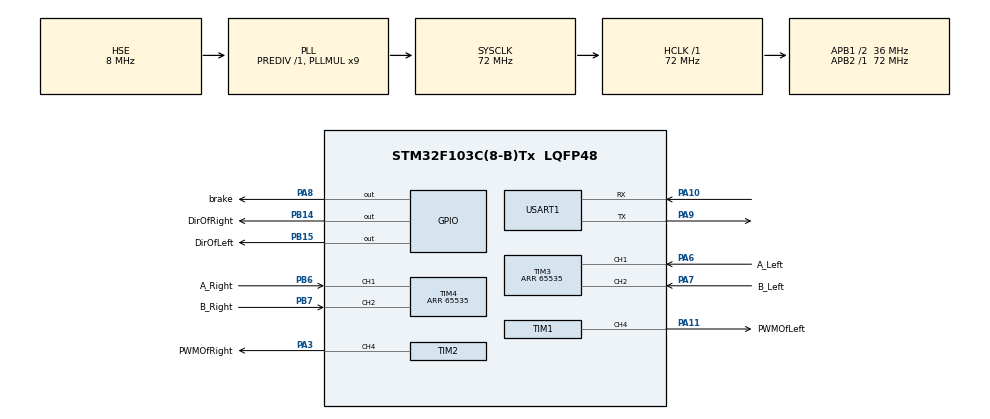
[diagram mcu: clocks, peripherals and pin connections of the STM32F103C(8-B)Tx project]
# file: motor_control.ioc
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Dma.Request0=USART1_TX
Dma.Request1=USART1_RX
Dma.USART1_RX.1.Direction=DMA_PERIPH_TO_MEMORY
Dma.USART1_RX.1.Instance=DMA1_Channel5
Dma.USART1_RX.1.MemDataAlignment=DMA_MDATAALIGN_BYTE
Dma.USART1_RX.1.MemInc=DMA_MINC_ENABLE
Dma.USART1_RX.1.Mode=DMA_CIRCULAR
Dma.USART1_RX.1.PeriphDataAlignment=DMA_PDATAALIGN_BYTE
Dma.USART1_RX.1.PeriphInc=DMA_PINC_DISABLE
Dma.USART1_RX.1.Priority=DMA_PRIORITY_MEDIUM
Dma.USART1_TX.0.Direction=DMA_MEMORY_TO_PERIPH
Dma.USART1_TX.0.Instance=DMA1_Channel4
Dma.USART1_TX.0.MemDataAlignment=DMA_MDATAALIGN_BYTE
Dma.USART1_TX.0.MemInc=DMA_MINC_ENABLE
Dma.USART1_TX.0.Mode=DMA_NORMAL
Dma.USART1_TX.0.PeriphDataAlignment=DMA_PDATAALIGN_BYTE
Dma.USART1_TX.0.PeriphInc=DMA_PINC_DISABLE
Dma.USART1_TX.0.Priority=DMA_PRIORITY_MEDIUM
Mcu.Family=STM32F1
Mcu.Name=STM32F103C(8-B)Tx
Mcu.Package=LQFP48
NVIC.DMA1_Channel4_IRQn=true\:3\:0\:true\:false\:true\:false\:true
NVIC.DMA1_Channel5_IRQn=true\:3\:0\:true\:false\:true\:false\:true
NVIC.PriorityGroup=NVIC_PRIORITYGROUP_4
NVIC.USART1_IRQn=true\:0\:0\:false\:false\:true\:true\:true
PA10.Mode=Asynchronous
PA10.Signal=USART1_RX
PA11.GPIO_Label=PWMOfLeft
PA11.Signal=S_TIM1_CH4
PA13.Mode=Serial_Wire
PA13.Signal=SYS_JTMS-SWDIO
PA14.Mode=Serial_Wire
PA14.Signal=SYS_JTCK-SWCLK
PA3.GPIO_Label=PWMOfRight
PA3.Signal=S_TIM2_CH4
PA6.GPIO_Label=A_Left
PA6.GPIO_PuPd=GPIO_PULLUP
PA6.Signal=S_TIM3_CH1
PA7.GPIO_Label=B_Left
PA7.GPIO_PuPd=GPIO_PULLUP
PA7.Signal=S_TIM3_CH2
PA8.GPIO_Label=brake
PA8.GPIO_PuPd=GPIO_PULLUP
PA8.Signal=GPIO_Output
PA9.Mode=Asynchronous
PA9.Signal=USART1_TX
PB14.GPIO_Label=DirOfRight
PB14.GPIO_Speed=GPIO_SPEED_FREQ_MEDIUM
PB14.PinState=GPIO_PIN_RESET
PB14.Signal=GPIO_Output
PB15.GPIO_Label=DirOfLeft
PB15.GPIO_Speed=GPIO_SPEED_FREQ_MEDIUM
PB15.Signal=GPIO_Output
PB6.GPIO_Label=A_Right
PB6.GPIO_PuPd=GPIO_PULLUP
PB6.Signal=S_TIM4_CH1
PB7.GPIO_Label=B_Right
PB7.GPIO_PuPd=GPIO_PULLUP
PB7.Signal=S_TIM4_CH2
PD0-OSC_IN.Mode=HSE-External-Oscillator
PD0-OSC_IN.Signal=RCC_OSC_IN
PD1-OSC_OUT.Mode=HSE-External-Oscillator
PD1-OSC_OUT.Signal=RCC_OSC_OUT
ProjectManager.HeapSize=0x200
ProjectManager.StackSize=0x400
ProjectManager.TargetToolchain=STM32CubeIDE
RCC.AHBFreq_Value=72000000
RCC.APB1CLKDivider=RCC_HCLK_DIV2
RCC.APB1Freq_Value=36000000
RCC.APB1TimFreq_Value=72000000
RCC.APB2Freq_Value=72000000
RCC.APB2TimFreq_Value=72000000
RCC.HCLKFreq_Value=72000000
RCC.PLLMUL=RCC_PLL_MUL9
RCC.PLLSourceVirtual=RCC_PLLSOURCE_HSE
RCC.SYSCLKFreq_VALUE=72000000
RCC.SYSCLKSource=RCC_SYSCLKSOURCE_PLLCLK
RCC.USBFreq_Value=72000000
SH.S_TIM1_CH4.0=TIM1_CH4,PWM Generation4 CH4
SH.S_TIM2_CH4.0=TIM2_CH4,PWM Generation4 CH4
SH.S_TIM3_CH1.0=TIM3_CH1,Encoder_Interface
SH.S_TIM3_CH2.0=TIM3_CH2,Encoder_Interface
SH.S_TIM4_CH1.0=TIM4_CH1,Encoder_Interface
SH.S_TIM4_CH2.0=TIM4_CH2,Encoder_Interface
TIM1.Channel-PWM\ Generation4\ CH4=TIM_CHANNEL_4
TIM1.Period=10001
TIM1.Prescaler=0
TIM2.Channel-PWM\ Generation4\ CH4=TIM_CHANNEL_4
TIM2.Period=10001
TIM2.Prescaler=0
TIM3.EncoderMode=TIM_ENCODERMODE_TI12
TIM3.IC1Filter=5
TIM3.IC2Filter=5
TIM3.Period=65535
TIM4.EncoderMode=TIM_ENCODERMODE_TI12
TIM4.IC1Filter=5
TIM4.IC2Filter=5
TIM4.Period=65535
USART1.VirtualMode=VM_ASYNC
board=custom

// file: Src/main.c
/* USER CODE BEGIN Header */
/**
  ******************************************************************************
  * @file           : main.c
  * @brief          : Main program body
  ******************************************************************************
  * @attention
  *
  * <h2><center>&copy; Copyright (c) 2019 STMicroelectronics.
  * All rights reserved.</center></h2>
  *
  * This software component is licensed by ST under BSD 3-Clause license,
  * the "License"; You may not use this file except in compliance with the
  * License. You may obtain a copy of the License at:
  *                        opensource.org/licenses/BSD-3-Clause
  *
  ******************************************************************************
  */
/* USER CODE END Header */

#include "main.h"

/* USER CODE BEGIN Includes */
#include "motor.h"
#include "my_uart.h"
/* USER CODE END Includes */

TIM_HandleTypeDef htim1;
TIM_HandleTypeDef htim2;
TIM_HandleTypeDef htim3;
TIM_HandleTypeDef htim4;

UART_HandleTypeDef huart1;
DMA_HandleTypeDef hdma_usart1_tx;
DMA_HandleTypeDef hdma_usart1_rx;

void SystemClock_Config(void);
static void MX_GPIO_Init(void);
static void MX_DMA_Init(void);
static void MX_TIM1_Init(void);
static void MX_TIM2_Init(void);
static void MX_TIM3_Init(void);
static void MX_TIM4_Init(void);
static void MX_USART1_UART_Init(void);

int main(void)
{
  /* USER CODE BEGIN 1 */
	uint8_t data[11];
	FloatToUnsignedChar ftuc;
  /* USER CODE END 1 */

  /* MCU Configuration--------------------------------------------------------*/

  /* Reset of all peripherals, Initializes the Flash interface and the Systick. */
  HAL_Init();

  /* Configure the system clock */
  SystemClock_Config();

  /* Initialize all configured peripherals */
  MX_GPIO_Init();
  MX_DMA_Init();
  MX_TIM1_Init();
  MX_TIM2_Init();
  MX_TIM3_Init();
  MX_TIM4_Init();
  MX_USART1_UART_Init();
  /* USER CODE BEGIN 2 */
  motor_init();
  my_uart_init();
  /* USER CODE END 2 */

  /* Infinite loop */
  /* USER CODE BEGIN WHILE */
  while (1)
  {
	data[0]=0xed;data[10]=0xde;data[5]=0xaa;
	ftuc.F32=x_position;
	data[1]=ftuc.U8.low;data[2]=ftuc.U8.mlow;data[3]=ftuc.U8.mhigh;data[4]=ftuc.U8.high;
	ftuc.F32=y_position;
	data[6]=ftuc.U8.low;data[7]=ftuc.U8.mlow;data[8]=ftuc.U8.mhigh;data[9]=ftuc.U8.high;
	HAL_UART_Transmit_DMA(&huart1, data, 11);
	HAL_Delay(15);
    /* USER CODE END WHILE */

  }
}

void SystemClock_Config(void)
{
  RCC_OscInitTypeDef RCC_OscInitStruct = {0};
  RCC_ClkInitTypeDef RCC_ClkInitStruct = {0};

  /** Initializes the CPU, AHB and APB busses clocks
  */
  RCC_OscInitStruct.OscillatorType = RCC_OSCILLATORTYPE_HSE;
  RCC_OscInitStruct.HSEState = RCC_HSE_ON;
  RCC_OscInitStruct.HSEPredivValue = RCC_HSE_PREDIV_DIV1;
  RCC_OscInitStruct.HSIState = RCC_HSI_ON;
  RCC_OscInitStruct.PLL.PLLState = RCC_PLL_ON;
  RCC_OscInitStruct.PLL.PLLSource = RCC_PLLSOURCE_HSE;
  RCC_OscInitStruct.PLL.PLLMUL = RCC_PLL_MUL9;
  if (HAL_RCC_OscConfig(&RCC_OscInitStruct) != HAL_OK)
  {
    Error_Handler();
  }
  /** Initializes the CPU, AHB and APB busses clocks
  */
  RCC_ClkInitStruct.ClockType = RCC_CLOCKTYPE_HCLK|RCC_CLOCKTYPE_SYSCLK
                              |RCC_CLOCKTYPE_PCLK1|RCC_CLOCKTYPE_PCLK2;
  RCC_ClkInitStruct.SYSCLKSource = RCC_SYSCLKSOURCE_PLLCLK;
  RCC_ClkInitStruct.AHBCLKDivider = RCC_SYSCLK_DIV1;
  RCC_ClkInitStruct.APB1CLKDivider = RCC_HCLK_DIV2;
  RCC_ClkInitStruct.APB2CLKDivider = RCC_HCLK_DIV1;

  if (HAL_RCC_ClockConfig(&RCC_ClkInitStruct, FLASH_LATENCY_2) != HAL_OK)
  {
    Error_Handler();
  }
}

static void MX_TIM1_Init(void)
{

  TIM_MasterConfigTypeDef sMasterConfig = {0};
  TIM_OC_InitTypeDef sConfigOC = {0};
  TIM_BreakDeadTimeConfigTypeDef sBreakDeadTimeConfig = {0};

  htim1.Instance = TIM1;
  htim1.Init.Prescaler = 0;
  htim1.Init.CounterMode = TIM_COUNTERMODE_UP;
  htim1.Init.Period = 10001;
  htim1.Init.ClockDivision = TIM_CLOCKDIVISION_DIV1;
  htim1.Init.RepetitionCounter = 0;
  htim1.Init.AutoReloadPreload = TIM_AUTORELOAD_PRELOAD_DISABLE;
  if (HAL_TIM_PWM_Init(&htim1) != HAL_OK)
  {
    Error_Handler();
  }
  sMasterConfig.MasterOutputTrigger = TIM_TRGO_RESET;
  sMasterConfig.MasterSlaveMode = TIM_MASTERSLAVEMODE_DISABLE;
  if (HAL_TIMEx_MasterConfigSynchronization(&htim1, &sMasterConfig) != HAL_OK)
  {
    Error_Handler();
  }
  sConfigOC.OCMode = TIM_OCMODE_PWM1;
  sConfigOC.Pulse = 0;
  sConfigOC.OCPolarity = TIM_OCPOLARITY_HIGH;
  sConfigOC.OCFastMode = TIM_OCFAST_DISABLE;
  sConfigOC.OCIdleState = TIM_OCIDLESTATE_RESET;
  sConfigOC.OCNIdleState = TIM_OCNIDLESTATE_RESET;
  if (HAL_TIM_PWM_ConfigChannel(&htim1, &sConfigOC, TIM_CHANNEL_4) != HAL_OK)
  {
    Error_Handler();
  }
  sBreakDeadTimeConfig.OffStateRunMode = TIM_OSSR_DISABLE;
  sBreakDeadTimeConfig.OffStateIDLEMode = TIM_OSSI_DISABLE;
  sBreakDeadTimeConfig.LockLevel = TIM_LOCKLEVEL_OFF;
  sBreakDeadTimeConfig.DeadTime = 0;
  sBreakDeadTimeConfig.BreakState = TIM_BREAK_DISABLE;
  sBreakDeadTimeConfig.BreakPolarity = TIM_BREAKPOLARITY_HIGH;
  sBreakDeadTimeConfig.AutomaticOutput = TIM_AUTOMATICOUTPUT_DISABLE;
  if (HAL_TIMEx_ConfigBreakDeadTime(&htim1, &sBreakDeadTimeConfig) != HAL_OK)
  {
    Error_Handler();
  }
  HAL_TIM_MspPostInit(&htim1);

}

static void MX_TIM2_Init(void)
{

  TIM_MasterConfigTypeDef sMasterConfig = {0};
  TIM_OC_InitTypeDef sConfigOC = {0};

  htim2.Instance = TIM2;
  htim2.Init.Prescaler = 0;
  htim2.Init.CounterMode = TIM_COUNTERMODE_UP;
  htim2.Init.Period = 10001;
  htim2.Init.ClockDivision = TIM_CLOCKDIVISION_DIV1;
  htim2.Init.AutoReloadPreload = TIM_AUTORELOAD_PRELOAD_DISABLE;
  if (HAL_TIM_PWM_Init(&htim2) != HAL_OK)
  {
    Error_Handler();
  }
  sMasterConfig.MasterOutputTrigger = TIM_TRGO_RESET;
  sMasterConfig.MasterSlaveMode = TIM_MASTERSLAVEMODE_DISABLE;
  if (HAL_TIMEx_MasterConfigSynchronization(&htim2, &sMasterConfig) != HAL_OK)
  {
    Error_Handler();
  }
  sConfigOC.OCMode = TIM_OCMODE_PWM1;
  sConfigOC.Pulse = 0;
  sConfigOC.OCPolarity = TIM_OCPOLARITY_HIGH;
  sConfigOC.OCFastMode = TIM_OCFAST_DISABLE;
  if (HAL_TIM_PWM_ConfigChannel(&htim2, &sConfigOC, TIM_CHANNEL_4) != HAL_OK)
  {
    Error_Handler();
  }
  HAL_TIM_MspPostInit(&htim2);

}

static void MX_TIM3_Init(void)
{

  TIM_Encoder_InitTypeDef sConfig = {0};
  TIM_MasterConfigTypeDef sMasterConfig = {0};

  htim3.Instance = TIM3;
  htim3.Init.Prescaler = 0;
  htim3.Init.CounterMode = TIM_COUNTERMODE_UP;
  htim3.Init.Period = 65535;
  htim3.Init.ClockDivision = TIM_CLOCKDIVISION_DIV1;
  htim3.Init.AutoReloadPreload = TIM_AUTORELOAD_PRELOAD_DISABLE;
  sConfig.EncoderMode = TIM_ENCODERMODE_TI12;
  sConfig.IC1Polarity = TIM_ICPOLARITY_RISING;
  sConfig.IC1Selection = TIM_ICSELECTION_DIRECTTI;
  sConfig.IC1Prescaler = TIM_ICPSC_DIV1;
  sConfig.IC1Filter = 5;
  sConfig.IC2Polarity = TIM_ICPOLARITY_RISING;
  sConfig.IC2Selection = TIM_ICSELECTION_DIRECTTI;
  sConfig.IC2Prescaler = TIM_ICPSC_DIV1;
  sConfig.IC2Filter = 5;
  if (HAL_TIM_Encoder_Init(&htim3, &sConfig) != HAL_OK)
  {
    Error_Handler();
  }
  sMasterConfig.MasterOutputTrigger = TIM_TRGO_RESET;
  sMasterConfig.MasterSlaveMode = TIM_MASTERSLAVEMODE_DISABLE;
  if (HAL_TIMEx_MasterConfigSynchronization(&htim3, &sMasterConfig) != HAL_OK)
  {
    Error_Handler();
  }

}

static void MX_TIM4_Init(void)
{

  TIM_Encoder_InitTypeDef sConfig = {0};
  TIM_MasterConfigTypeDef sMasterConfig = {0};

  htim4.Instance = TIM4;
  htim4.Init.Prescaler = 0;
  htim4.Init.CounterMode = TIM_COUNTERMODE_UP;
  htim4.Init.Period = 65535;
  htim4.Init.ClockDivision = TIM_CLOCKDIVISION_DIV1;
  htim4.Init.AutoReloadPreload = TIM_AUTORELOAD_PRELOAD_DISABLE;
  sConfig.EncoderMode = TIM_ENCODERMODE_TI12;
  sConfig.IC1Polarity = TIM_ICPOLARITY_RISING;
  sConfig.IC1Selection = TIM_ICSELECTION_DIRECTTI;
  sConfig.IC1Prescaler = TIM_ICPSC_DIV1;
  sConfig.IC1Filter = 5;
  sConfig.IC2Polarity = TIM_ICPOLARITY_RISING;
  sConfig.IC2Selection = TIM_ICSELECTION_DIRECTTI;
  sConfig.IC2Prescaler = TIM_ICPSC_DIV1;
  sConfig.IC2Filter = 5;
  if (HAL_TIM_Encoder_Init(&htim4, &sConfig) != HAL_OK)
  {
    Error_Handler();
  }
  sMasterConfig.MasterOutputTrigger = TIM_TRGO_RESET;
  sMasterConfig.MasterSlaveMode = TIM_MASTERSLAVEMODE_DISABLE;
  if (HAL_TIMEx_MasterConfigSynchronization(&htim4, &sMasterConfig) != HAL_OK)
  {
    Error_Handler();
  }

}

static void MX_USART1_UART_Init(void)
{

  huart1.Instance = USART1;
  huart1.Init.BaudRate = 115200;
  huart1.Init.WordLength = UART_WORDLENGTH_8B;
  huart1.Init.StopBits = UART_STOPBITS_1;
  huart1.Init.Parity = UART_PARITY_NONE;
  huart1.Init.Mode = UART_MODE_TX_RX;
  huart1.Init.HwFlowCtl = UART_HWCONTROL_NONE;
  huart1.Init.OverSampling = UART_OVERSAMPLING_16;
  if (HAL_UART_Init(&huart1) != HAL_OK)
  {
    Error_Handler();
  }

}

static void MX_DMA_Init(void)
{

  /* DMA controller clock enable */
  __HAL_RCC_DMA1_CLK_ENABLE();

  /* DMA interrupt init */
  /* DMA1_Channel4_IRQn interrupt configuration */
  HAL_NVIC_SetPriority(DMA1_Channel4_IRQn, 3, 0);
  HAL_NVIC_EnableIRQ(DMA1_Channel4_IRQn);
  /* DMA1_Channel5_IRQn interrupt configuration */
  HAL_NVIC_SetPriority(DMA1_Channel5_IRQn, 3, 0);
  HAL_NVIC_EnableIRQ(DMA1_Channel5_IRQn);

}

static void MX_GPIO_Init(void)
{
  GPIO_InitTypeDef GPIO_InitStruct = {0};

  /* GPIO Ports Clock Enable */
  __HAL_RCC_GPIOD_CLK_ENABLE();
  __HAL_RCC_GPIOA_CLK_ENABLE();
  __HAL_RCC_GPIOB_CLK_ENABLE();

  /*Configure GPIO pin Output Level */
  HAL_GPIO_WritePin(GPIOB, DirOfRight_Pin|DirOfLeft_Pin, GPIO_PIN_RESET);

  /*Configure GPIO pin Output Level */
  HAL_GPIO_WritePin(brake_GPIO_Port, brake_Pin, GPIO_PIN_RESET);

  /*Configure GPIO pins : DirOfRight_Pin DirOfLeft_Pin */
  GPIO_InitStruct.Pin = DirOfRight_Pin|DirOfLeft_Pin;
  GPIO_InitStruct.Mode = GPIO_MODE_OUTPUT_PP;
  GPIO_InitStruct.Pull = GPIO_NOPULL;
  GPIO_InitStruct.Speed = GPIO_SPEED_FREQ_MEDIUM;
  HAL_GPIO_Init(GPIOB, &GPIO_InitStruct);

  /*Configure GPIO pin : brake_Pin */
  GPIO_InitStruct.Pin = brake_Pin;
  GPIO_InitStruct.Mode = GPIO_MODE_OUTPUT_PP;
  GPIO_InitStruct.Pull = GPIO_PULLUP;
  GPIO_InitStruct.Speed = GPIO_SPEED_FREQ_LOW;
  HAL_GPIO_Init(brake_GPIO_Port, &GPIO_InitStruct);

}

void Error_Handler(void)
{
}

/************************ (C) COPYRIGHT STMicroelectronics *****END OF FILE****/
